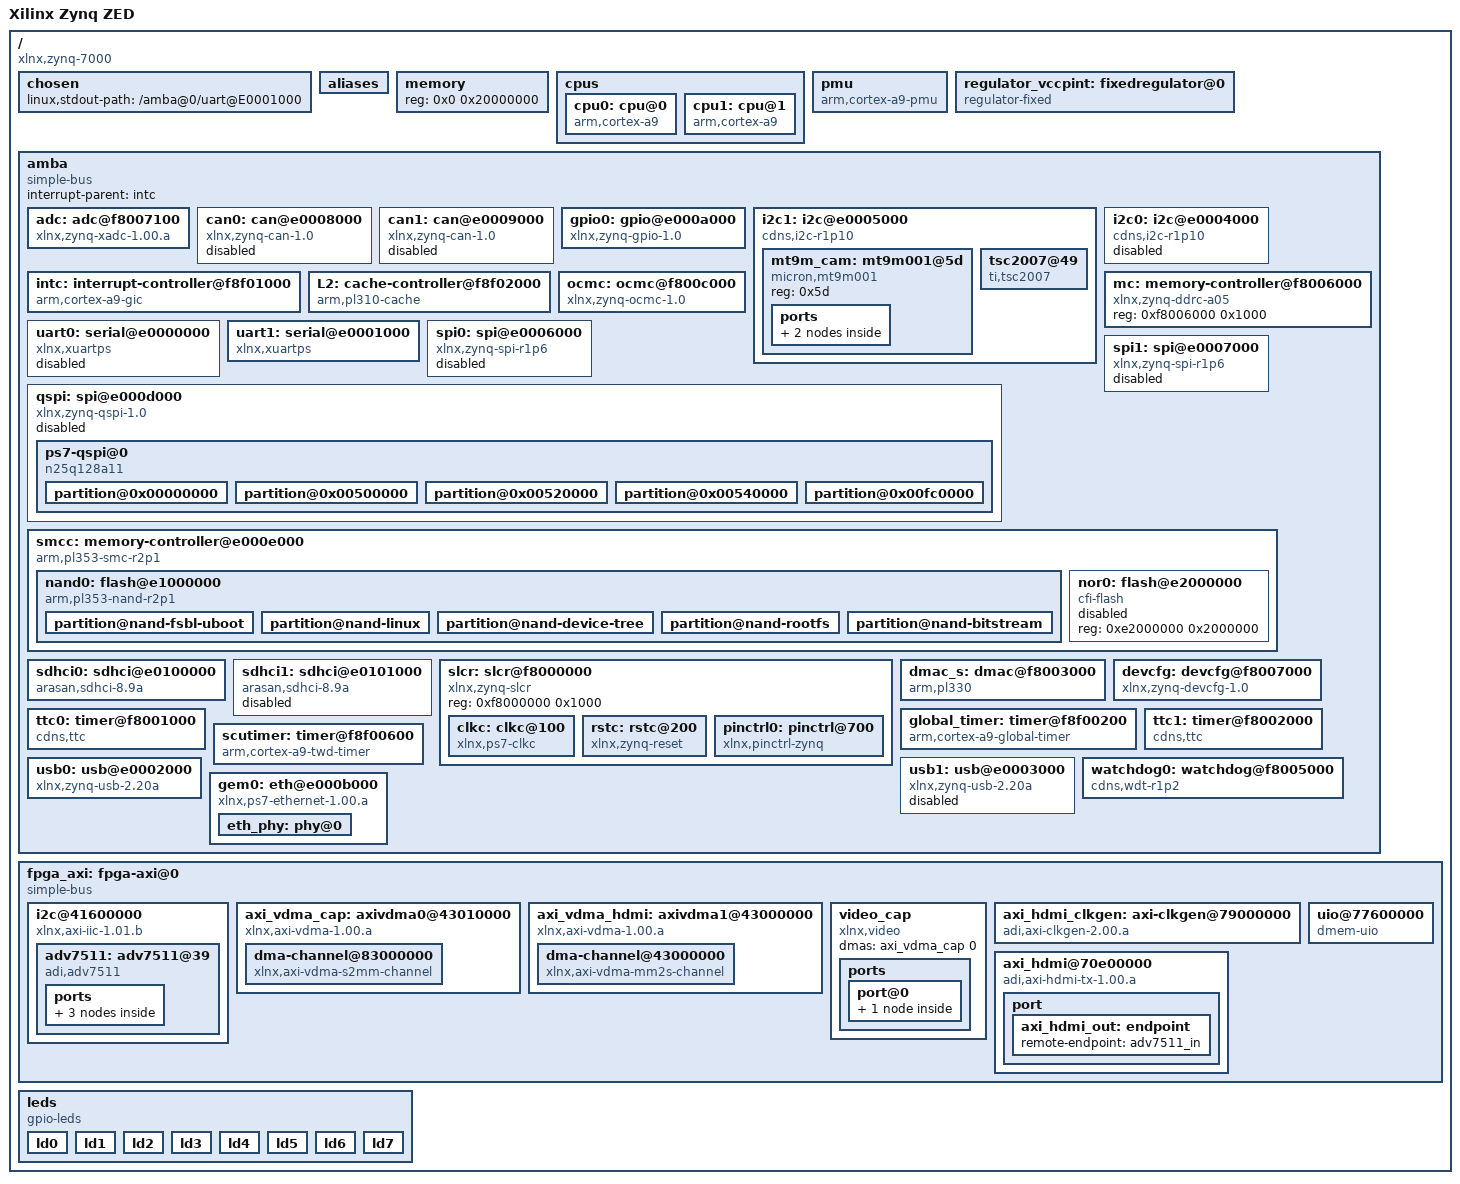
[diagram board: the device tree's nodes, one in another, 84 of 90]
/dts-v1/;

/* copy from linux header file for device tree

#define GPIO_ACTIVE_HIGH 	0
#define GPIO_ACTIVE_LOW 	1
*/

/ {
	#address-cells = <0x1>;
	#size-cells = <0x1>;
	compatible = "xlnx,zynq-7000";
	interrupt-parent = <&intc>;
	model = "Xilinx Zynq ZED";

	chosen {
		/*bootargs = "console=ttyPS0,115200 root=/dev/ram rw earlyprintk";*/
		linux,stdout-path = "/amba@0/uart@E0001000";
	};

	aliases {
		ethernet0 = "/amba/eth@e000b000";
		serial0 = "/amba/serial@e0001000";
	};

	memory {
		device_type = "memory";
		reg = <0x0 0x20000000>;
	};

	cpus {
		#address-cells = <1>;
		#size-cells = <0>;

		cpu0: cpu@0 {
			compatible = "arm,cortex-a9";
			device_type = "cpu";
			reg = <0>;
			clocks = <&clkc 3>;
			clock-latency = <1000>;
			cpu0-supply = <&regulator_vccpint>;
			operating-points = <
				/* kHz    uV */
				666667  1000000
				333334  1000000
			>;
		};

		cpu1: cpu@1 {
			compatible = "arm,cortex-a9";
			device_type = "cpu";
			reg = <1>;
			clocks = <&clkc 3>;
		};
	};

	pmu {
		compatible = "arm,cortex-a9-pmu";
		interrupts = <0 5 4>, <0 6 4>;
		interrupt-parent = <&intc>;
		reg = <0xf8891000 0x1000 0xf8893000 0x1000>;
	};

	regulator_vccpint: fixedregulator@0 {
		compatible = "regulator-fixed";
		regulator-name = "VCCPINT";
		regulator-min-microvolt = <1000000>;
		regulator-max-microvolt = <1000000>;
		regulator-boot-on;
		regulator-always-on;
	};

	amba: amba {
		compatible = "simple-bus";
		#address-cells = <1>;
		#size-cells = <1>;
		interrupt-parent = <&intc>;
		ranges;

		adc: adc@f8007100 {
			compatible = "xlnx,zynq-xadc-1.00.a";
			reg = <0xf8007100 0x20>;
			interrupts = <0 7 4>;
			interrupt-parent = <&intc>;
			clocks = <&clkc 12>;
		};

		can0: can@e0008000 {
			compatible = "xlnx,zynq-can-1.0";
			status = "disabled";
			clocks = <&clkc 19>, <&clkc 36>;
			clock-names = "can_clk", "pclk";
			reg = <0xe0008000 0x1000>;
			interrupts = <0 28 4>;
			interrupt-parent = <&intc>;
			tx-fifo-depth = <0x40>;
			rx-fifo-depth = <0x40>;
		};

		can1: can@e0009000 {
			compatible = "xlnx,zynq-can-1.0";
			status = "disabled";
			clocks = <&clkc 20>, <&clkc 37>;
			clock-names = "can_clk", "pclk";
			reg = <0xe0009000 0x1000>;
			interrupts = <0 51 4>;
			interrupt-parent = <&intc>;
			tx-fifo-depth = <0x40>;
			rx-fifo-depth = <0x40>;
		};

		gpio0: gpio@e000a000 {
			compatible = "xlnx,zynq-gpio-1.0";
			#gpio-cells = <2>;
			clocks = <&clkc 42>;
			gpio-controller;
			interrupt-controller;
			#interrupt-cells = <2>;
			interrupt-parent = <&intc>;
			interrupts = <0 20 4>;
			reg = <0xe000a000 0x1000>;
		};

		i2c1: i2c@e0005000 {
			compatible = "cdns,i2c-r1p10";
			status = "okay";
			clocks = <&clkc 39>;
			interrupt-parent = <&intc>;
			interrupts = <0 48 4>;
			reg = <0xe0005000 0x1000>;
			#address-cells = <1>;
			#size-cells = <0>;
			clock-frequency = <400000>;
			mt9m_cam: mt9m001@5d {
				compatible = "micron,mt9m001";
				reg = <0x5d>;
				ports {
					#address-cells = <1>;
					#size-cells = <0>;
					port@0 {
						reg = <0>;
						xlnx,video-format = <2>;
						xlnx,video-width = <8>;
						cam_out: endpoint {
							remote-endpoint = <&vid_cap_in>;
						};
					};
				};
			};
		};

		i2c0: i2c@e0004000 {
			compatible = "cdns,i2c-r1p10";
			status = "disabled";
			clocks = <&clkc 38>;
			interrupt-parent = <&intc>;
			interrupts = <0 25 4>;
			reg = <0xe0004000 0x1000>;
			#address-cells = <1>;
			#size-cells = <0>;
		};

		intc: interrupt-controller@f8f01000 {
			compatible = "arm,cortex-a9-gic";
			#interrupt-cells = <3>;
			interrupt-controller;
			reg = <0xF8F01000 0x1000>,
			      <0xF8F00100 0x100>;
		};

		L2: cache-controller@f8f02000 {
			compatible = "arm,pl310-cache";
			reg = <0xf8f02000 0x1000>;
			interrupts = <0 2 4>;
			arm,data-latency = <3 2 2>;
			arm,tag-latency = <2 2 2>;
			cache-unified;
			cache-level = <2>;
		};

		mc: memory-controller@f8006000 {
			compatible = "xlnx,zynq-ddrc-a05";
			reg = <0xf8006000 0x1000>;
		};

		ocmc: ocmc@f800c000 {
			compatible = "xlnx,zynq-ocmc-1.0";
			interrupt-parent = <&intc>;
			interrupts = <0 3 4>;
			reg = <0xf800c000 0x1000>;
		};

		uart0: serial@e0000000 {
			compatible = "xlnx,xuartps", "cdns,uart-r1p8";
			status = "disabled";
			clocks = <&clkc 23>, <&clkc 40>;
			clock-names = "uart_clk", "pclk";
			reg = <0xe0000000 0x1000>;
			interrupts = <0 27 4>;
		};

		uart1: serial@e0001000 {
			compatible = "xlnx,xuartps", "cdns,uart-r1p8";
			status = "okay";
			clocks = <&clkc 24>, <&clkc 41>;
			clock-names = "uart_clk", "pclk";
			reg = <0xe0001000 0x1000>;
			interrupts = <0 50 4>;
		};

		spi0: spi@e0006000 {
			compatible = "xlnx,zynq-spi-r1p6";
			reg = <0xe0006000 0x1000>;
			status = "disabled";
			interrupt-parent = <&intc>;
			interrupts = <0 26 4>;
			clocks = <&clkc 25>, <&clkc 34>;
			clock-names = "ref_clk", "pclk";
			#address-cells = <1>;
			#size-cells = <0>;
		};

		spi1: spi@e0007000 {
			compatible = "xlnx,zynq-spi-r1p6";
			reg = <0xe0007000 0x1000>;
			status = "disabled";
			interrupt-parent = <&intc>;
			interrupts = <0 49 4>;
			clocks = <&clkc 26>, <&clkc 35>;
			clock-names = "ref_clk", "pclk";
			#address-cells = <1>;
			#size-cells = <0>;
		};

		qspi: spi@e000d000 {
			clock-names = "ref_clk", "pclk";
			clocks = <&clkc 10>, <&clkc 43>;
			compatible = "xlnx,zynq-qspi-1.0";
			status = "disabled";
			interrupt-parent = <&intc>;
			interrupts = <0 19 4>;
			reg = <0xe000d000 0x1000>;
			#address-cells = <1>;
			#size-cells = <0>;
			is-dual = <0>;
			num-cs = <1>;

			ps7-qspi@0 {
				#address-cells = <0x1>;
				#size-cells = <0x1>;
				compatible = "n25q128a11";
				reg = <0x0>;
				spi-max-frequency = <0x2faf080>;

				partition@0x00000000 {
					label = "boot";
					reg = <0x0 0x500000>;
				};
				partition@0x00500000 {
					label = "bootenv";
					reg = <0x500000 0x20000>;
				};
				partition@0x00520000 {
					label = "config";
					reg = <0x520000 0x20000>;
				};
				partition@0x00540000 {
					label = "image";
					reg = <0x540000 0xa80000>;
				};
				partition@0x00fc0000 {
					label = "spare";
					reg = <0xfc0000 0x0>;
				};
			};
		};

		smcc: memory-controller@e000e000 {
			#address-cells = <1>;
			#size-cells = <1>;
			status = "okay";
			clock-names = "memclk", "aclk";
			clocks = <&clkc 11>, <&clkc 44>;
			compatible = "arm,pl353-smc-r2p1";
			interrupt-parent = <&intc>;
			interrupts = <0 18 4>;
			ranges;
			reg = <0xe000e000 0x1000>;

			nand0: flash@e1000000 {
				status = "okay";
				compatible = "arm,pl353-nand-r2p1";
				reg = <0xe1000000 0x1000000>;
				#address-cells = <1>;
				#size-cells = <1>;
			};

			nor0: flash@e2000000 {
				status = "disabled";
				compatible = "cfi-flash";
				reg = <0xe2000000 0x2000000>;
				#address-cells = <1>;
				#size-cells = <1>;
			};
		};

		sdhci0: sdhci@e0100000 {
			compatible = "arasan,sdhci-8.9a";
			status = "okay";
			clock-names = "clk_xin", "clk_ahb";
			clocks = <&clkc 21>, <&clkc 32>;
			interrupt-parent = <&intc>;
			interrupts = <0 24 4>;
			reg = <0xe0100000 0x1000>;
		};

		sdhci1: sdhci@e0101000 {
			compatible = "arasan,sdhci-8.9a";
			status = "disabled";
			clock-names = "clk_xin", "clk_ahb";
			clocks = <&clkc 22>, <&clkc 33>;
			interrupt-parent = <&intc>;
			interrupts = <0 47 4>;
			reg = <0xe0101000 0x1000>;
		};

		slcr: slcr@f8000000 {
			#address-cells = <1>;
			#size-cells = <1>;
			compatible = "xlnx,zynq-slcr", "syscon", "simple-mfd";
			reg = <0xf8000000 0x1000>;
			ranges;

			clkc: clkc@100 {
				#clock-cells = <0x1>;
				compatible = "xlnx,ps7-clkc";
				fclk-enable = <0xf>;
				clock-output-names = "armpll", "ddrpll", "iopll", "cpu_6or4x",
						"cpu_3or2x", "cpu_2x", "cpu_1x", "ddr2x", "ddr3x",
						"dci", "lqspi", "smc", "pcap", "gem0", "gem1",
						"fclk0", "fclk1", "fclk2", "fclk3", "can0", "can1",
						"sdio0", "sdio1", "uart0", "uart1", "spi0", "spi1",
						"dma", "usb0_aper", "usb1_aper", "gem0_aper",
						"gem1_aper", "sdio0_aper", "sdio1_aper",
						"spi0_aper", "spi1_aper", "can0_aper", "can1_aper",
						"i2c0_aper", "i2c1_aper", "uart0_aper", "uart1_aper",
						"gpio_aper", "lqspi_aper", "smc_aper", "swdt",
						"dbg_trc", "dbg_apb";
				reg = <0x100 0x100>;
			};

			rstc: rstc@200 {
				compatible = "xlnx,zynq-reset";
				reg = <0x200 0x48>;
				#reset-cells = <1>;
				syscon = <&slcr>;
			};

			pinctrl0: pinctrl@700 {
				compatible = "xlnx,pinctrl-zynq";
				reg = <0x700 0x200>;
				syscon = <&slcr>;
			};
		};

		dmac_s: dmac@f8003000 {
			compatible = "arm,pl330", "arm,primecell";
			reg = <0xf8003000 0x1000>;
			interrupt-parent = <&intc>;
			interrupt-names = "abort", "dma0", "dma1", "dma2", "dma3",
				"dma4", "dma5", "dma6", "dma7";
			interrupts = <0 13 4>,
			             <0 14 4>, <0 15 4>,
			             <0 16 4>, <0 17 4>,
			             <0 40 4>, <0 41 4>,
			             <0 42 4>, <0 43 4>;
			#dma-cells = <1>;
			#dma-channels = <8>;
			#dma-requests = <4>;
			clocks = <&clkc 27>;
			clock-names = "apb_pclk";
		};

		devcfg: devcfg@f8007000 {
			compatible = "xlnx,zynq-devcfg-1.0";
			interrupt-parent = <&intc>;
			interrupts = <0 8 4>;
			reg = <0xf8007000 0x100>;
			clocks = <&clkc 12>, <&clkc 15>, <&clkc 16>, <&clkc 17>, <&clkc 18>;
			clock-names = "ref_clk", "fclk0", "fclk1", "fclk2", "fclk3";
			syscon = <&slcr>;
		};

		global_timer: timer@f8f00200 {
			compatible = "arm,cortex-a9-global-timer";
			reg = <0xf8f00200 0x20>;
			interrupts = <1 11 0x301>;
			interrupt-parent = <&intc>;
			clocks = <&clkc 4>;
		};

		ttc0: timer@f8001000 {
			interrupt-parent = <&intc>;
			interrupts = <0 10 4>, <0 11 4>, <0 12 4>;
			compatible = "cdns,ttc";
			clocks = <&clkc 6>;
			reg = <0xf8001000 0x1000>;
		};

		ttc1: timer@f8002000 {
			interrupt-parent = <&intc>;
			interrupts = <0 37 4>, <0 38 4>, <0 39 4>;
			compatible = "cdns,ttc";
			clocks = <&clkc 6>;
			reg = <0xf8002000 0x1000>;
		};

		scutimer: timer@f8f00600 {
			interrupt-parent = <&intc>;
			interrupts = <1 13 0x301>;
			compatible = "arm,cortex-a9-twd-timer";
			reg = <0xf8f00600 0x20>;
			clocks = <&clkc 4>;
		};

		usb0: usb@e0002000 {
			compatible = "xlnx,zynq-usb-2.20a", "chipidea,usb2";
			status = "okay";
			clocks = <&clkc 28>;
			interrupt-parent = <&intc>;
			interrupts = <0 21 4>;
			reg = <0xe0002000 0x1000>;
			phy_type = "ulpi";
			//dr_mode = "peripheral";
			//xlnx,phy-reset-gpio = <&gpio0 85 0>;
		};

		usb1: usb@e0003000 {
			compatible = "xlnx,zynq-usb-2.20a", "chipidea,usb2";
			status = "disabled";
			clocks = <&clkc 29>;
			interrupt-parent = <&intc>;
			interrupts = <0 44 4>;
			reg = <0xe0003000 0x1000>;
			phy_type = "ulpi";
		};

		watchdog0: watchdog@f8005000 {
			clocks = <&clkc 45>;
			compatible = "cdns,wdt-r1p2";
			interrupt-parent = <&intc>;
			interrupts = <0 9 1>;
			reg = <0xf8005000 0x1000>;
			timeout-sec = <10>;
		};

		gem0: eth@e000b000 {
			compatible = "xlnx,ps7-ethernet-1.00.a";
			reg = <0xe000b000 0x1000>;
			interrupts = <0 22 4>;
			interrupt-parent = <&intc>;
			#address-cells = <1>;
			#size-cells = <0>;
			clock-names = "ref_clk", "aper_clk";
			clocks = <&clkc 13 &clkc 30>;
			xlnx,enet-clk-freq-hz = <25000000>;
			xlnx,enet-reset = "MIO 11";
			xlnx,enet-slcr-1000mbps-div0 = <8>;
			xlnx,enet-slcr-1000mbps-div1 = <1>;
			xlnx,enet-slcr-100mbps-div0 = <8>;
			xlnx,enet-slcr-100mbps-div1 = <5>;
			xlnx,enet-slcr-10mbps-div0 = <8>;
			xlnx,enet-slcr-10mbps-div1 = <50>;
			xlnx,eth-mode = <1>;
			xlnx,has-mdio = <1>;
			xlnx,ptp-enet-clock = <111111115>;
			phy-handle = <&eth_phy>;
			phy-mode = "rgmii-id";

			eth_phy: phy@0 {
				device_type = "ethernet-phy";
				reg = <0>;
				marvell,reg-init = <0x3 0x10 0xff00 0x1e 0x3 0x11 0xfff0 0xa>;
			};
		};
	};

	fpga_axi: fpga-axi@0 {
		compatible = "simple-bus";
		#address-cells = <1>;
		#size-cells = <1>;
		ranges;

		i2c@41600000 {
			compatible = "xlnx,axi-iic-1.01.b", "xlnx,xps-iic-2.00.a";
			reg = <0x41600000 0x10000>;
			interrupt-parent = <&intc>;
			interrupts = <0 58 4>;
			clocks = <&clkc 15>;
			clock-names = "pclk";
			#size-cells = <0>;
			#address-cells = <1>;

			adv7511: adv7511@39 {
				compatible = "adi,adv7511";
				reg = <0x39>;
				adi,input-style = <2>;
				adi,input-id = <1>;
				adi,input-color-depth = <3>;
				adi,sync-pulse = <3>;
				adi,bit-justification = <1>;
				adi,up-conversion = <0>;
				adi,timing-generation-sequence = <0>;
				adi,vsync-polarity = <2>;
				adi,hsync-polarity = <2>;
				adi,tdms-clock-inversion;
				adi,clock-delay = <3>;
				#sound-dai-cells = <0>;
				ports {
					#address-cells = <1>;
					#size-cells = <0>;
					port@0 {
						reg = <0>;
						adv7511_in: endpoint {
							remote-endpoint = <&axi_hdmi_out>;
						};
					};
					port@1 {
						reg = <1>;
					};
				};
			};

		};

		axi_vdma_cap: axivdma0@43010000 {
			compatible = "xlnx,axi-vdma-1.00.a";
			#address-cells = <1>;
			#size-cells = <1>;
			#dma-cells = <1>;
			#dma-channels = <1>;
			reg = <0x43010000 0x10000>;
			xlnx,flush-fsync = <1>;
			xlnx,addrwidth = <32>;
			xlnx,num-fstores = <3>;
			dma-channel@83000000 {
				compatible = "xlnx,axi-vdma-s2mm-channel";
				interrupt-parent = <&intc>;
				interrupts = <0 57 4>;
				xlnx,datawidth = <64>;
				xlnx,genlock-mode = <1>;
			};
		};

		axi_vdma_hdmi: axivdma1@43000000 {
			compatible = "xlnx,axi-vdma-1.00.a";
			#address-cells = <1>;
			#size-cells = <1>;
			#dma-cells = <1>;
			#dma-channels = <1>;
			reg = <0x43000000 0x1000>;
			xlnx,flush-fsync = <1>;
			xlnx,addrwidth = <32>;
			xlnx,num-fstores = <3>;
			dma-channel@43000000 {
				compatible = "xlnx,axi-vdma-mm2s-channel";
				interrupts = <0 59 4>;
				xlnx,datawidth = <64>;
				xlnx,genlock-mode = <1>;
				xlnx,include-dre = <0>;
			};
		};

		video_cap {
			compatible = "xlnx,video";
			dmas = <&axi_vdma_cap 0>;
			dma-names = "port0";
			ports {
				#address-cells = <1>;
				#size-cells = <0>;
				port@0 {
					reg = <0>;
					direction = "input";
					vid_cap_in: endpoint {
						remote-endpoint = <&cam_out>;
					};
				};
			};
		};

		axi_hdmi_clkgen: axi-clkgen@79000000 {
			compatible = "adi,axi-clkgen-2.00.a";
			reg = <0x79000000 0x10000>;
			#clock-cells = <0>;
			clocks = <&clkc 16>;
		};

		axi_hdmi@70e00000 {
			compatible = "adi,axi-hdmi-tx-1.00.a";
			reg = <0x70e00000 0x10000>;
			dmas = <&axi_vdma_hdmi 0>;
			dma-names = "video";
			clocks = <&axi_hdmi_clkgen>;
			port {
				axi_hdmi_out: endpoint {
					remote-endpoint = <&adv7511_in>;
				};
			};
		};

	};

	leds {
		compatible = "gpio-leds";
		ld0 {
			label = "ld0:red";
			gpios = <&gpio0 73 0>;
		};
		ld1 {
			label = "ld1:red";
			gpios = <&gpio0 74 0>;
		};
		ld2 {
			label = "ld2:red";
			gpios = <&gpio0 75 0>;
		};
		ld3 {
			label = "ld3:red";
			gpios = <&gpio0 76 0>;
		};
		ld4 {
			label = "ld4:red";
			gpios = <&gpio0 77 0>;
		};

		ld5 {
			label = "ld5:red";
			gpios = <&gpio0 78 0>;
		};

		ld6 {
			label = "ld6:red";
			gpios = <&gpio0 79 0>;
		};

		ld7 {
			label = "ld7:red";
			gpios = <&gpio0 80 0>;
		};
	};
};

/*add for nand device	*/

&smcc {
	status = "okay";
	arm,addr25 = <0x0>;
	arm,nor-chip-sel0 = <0x0>;
	arm,nor-chip-sel1 = <0x0>;
	arm,sram-chip-sel0 = <0x0>;
	arm,sram-chip-sel1 = <0x0>;
};

&nand0 {
	status = "okay";
	arm,nand-cycle-t0 = <0x4>;
	arm,nand-cycle-t1 = <0x4>;
	arm,nand-cycle-t2 = <0x1>;
	arm,nand-cycle-t3 = <0x2>;
	arm,nand-cycle-t4 = <0x2>;
	arm,nand-cycle-t5 = <0x2>;
	arm,nand-cycle-t6 = <0x4>;
	partition@nand-fsbl-uboot {
		label = "nand-fsbl-uboot";
		reg = <0x0 0x100000>;
	};
	partition@nand-linux {
		label = "nand-linux";
		reg = <0x100000 0x500000>;
	};
	partition@nand-device-tree {
		label = "nand-device-tree";
		reg = <0x600000 0x20000>;
	};
	partition@nand-rootfs {
		label = "nand-rootfs";
		reg = <0x620000 0x5E0000>;
	};
	partition@nand-bitstream {
		label = "nand-bitstream";
		reg = <0xC00000 0x400000>;
	};
};

/*add for uio test*/

/*
&amba {
	ii2c@e0004000{
		compatible = "dmem-uio";
		reg = <0xe0004000 0x1000>;
	};
};
*/

&fpga_axi {
	uio@77600000{
		compatible = "dmem-uio";
		reg = <0x77600000 0x1000>;
 		uio,number-of-dynamic-regions = <1>;
		uio,dynamic-regions-sizes = <262144>;
	};
};

&i2c1 {
	tsc2007@49 { 
		compatible = "ti,tsc2007";
		reg = <0x49>;
		interrupt-parent = <&gpio0>;
		interrupts = <57 8>;
		gpios = <&gpio0 57 1>;
		ti,x-plate-ohms = <180>; 
		ti,poll-period = /bits/ 64 <30>; //in ms
	}; 
};
